# STM32WB55x register map
File version: 1.0
CPU: CM4 r0p1, little endian, 4 interrupt priority bits
Registers are 32-bit, read-write, reset 0x0 unless marked. A register's access mark holds for its fields unless they carry their own. Offsets are from the block's base; [hi:lo] are bit positions; {n}, {i} and the like mark numbered series; 'fields as' and 'values as' point back to an identical list.

## TIM2
Base 0x40000000
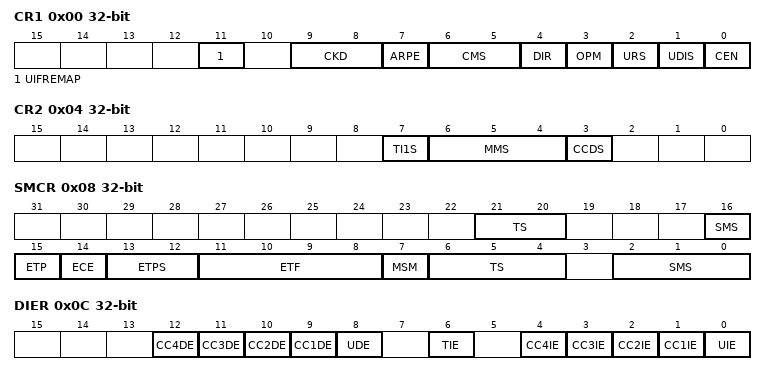
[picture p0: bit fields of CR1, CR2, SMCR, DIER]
0x00 CR1
  [11] UIFREMAP, [9:8] CKD, [7] ARPE, [6:5] CMS, [4] DIR, [3] OPM, [2] URS, [1] UDIS, [0] CEN
0x04 CR2
  [7] TI1S, [6:4] MMS, [3] CCDS
0x08 SMCR
  [21:20] TS, [16] SMS, [15] ETP, [14] ECE, [13:12] ETPS, [11:8] ETF, [7] MSM, [6:4] TS, [2:0] SMS
0x0C DIER
  [n+8] CC{n}DE (n=1..4), [8] UDE, [6] TIE, [n] CC{n}IE (n=1..4), [0] UIE
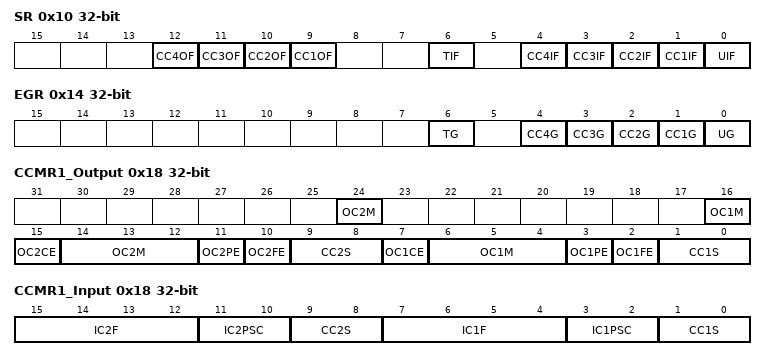
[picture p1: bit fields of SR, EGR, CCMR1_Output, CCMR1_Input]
0x10 SR
  [n+8] CC{n}OF (n=1..4), [6] TIF, [n] CC{n}IF (n=1..4), [0] UIF
0x14 EGR
  [6] TG, [n] CC{n}G (n=1..4), [0] UG
0x18 CCMR1_Output
  [24] OC2M, [16] OC1M, [15] OC2CE, [14:12] OC2M, [11] OC2PE, [10] OC2FE, [9:8] CC2S, [7] OC1CE, [6:4] OC1M, [3] OC1PE, [2] OC1FE, [1:0] CC1S
0x18 CCMR1_Input
  [15:12] IC2F, [11:10] IC2PSC, [9:8] CC2S, [7:4] IC1F, [3:2] IC1PSC, [1:0] CC1S
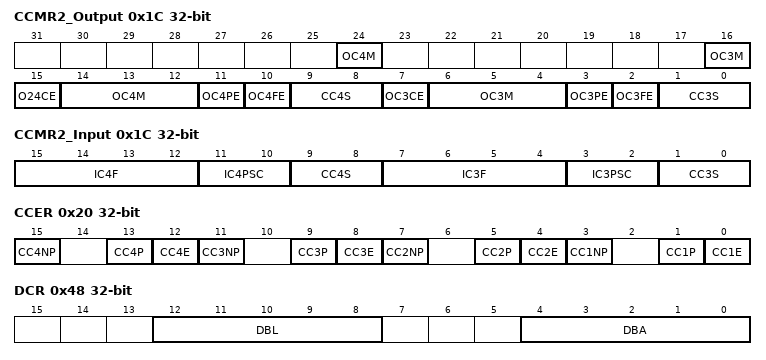
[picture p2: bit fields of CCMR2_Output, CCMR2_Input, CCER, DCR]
0x1C CCMR2_Output
  [24] OC4M, [16] OC3M, [15] O24CE, [14:12] OC4M, [11] OC4PE, [10] OC4FE, [9:8] CC4S, [7] OC3CE, [6:4] OC3M, [3] OC3PE, [2] OC3FE, [1:0] CC3S
0x1C CCMR2_Input
  [15:12] IC4F, [11:10] IC4PSC, [9:8] CC4S, [7:4] IC3F, [3:2] IC3PSC, [1:0] CC3S
0x20 CCER
  [4n-1] CC{n}NP (n=1..4), [4n-3] CC{n}P (n=1..4), [4n-4] CC{n}E (n=1..4)
0x24 CNT
0x28 PSC
  [15:0] PSC
0x2C ARR
{0x30+4i} CCR{i} (i=1..4)
0x48 DCR
  [12:8] DBL, [4:0] DBA
0x4C DMAR
  [15:0] DMAB
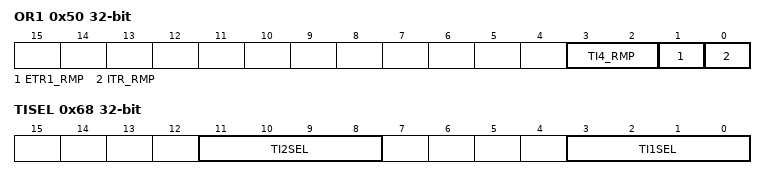
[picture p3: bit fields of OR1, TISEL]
0x50 OR1
  [3:2] TI4_RMP, [1] ETR1_RMP, [0] ITR_RMP
0x60 AF1
  [17:14] ETRSEL
0x68 TISEL
  [11:8] TI2SEL, [3:0] TI1SEL

## TIM16
Base 0x40014400
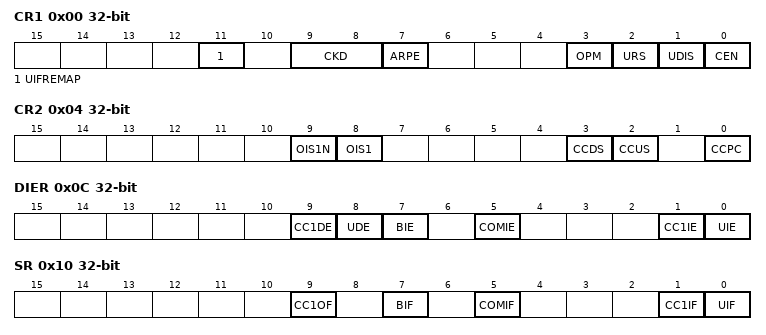
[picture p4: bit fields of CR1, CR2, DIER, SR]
0x00 CR1
  [11] UIFREMAP, [9:8] CKD, [7] ARPE, [3] OPM, [2] URS, [1] UDIS, [0] CEN
0x04 CR2
  [9] OIS1N, [8] OIS1, [3] CCDS, [2] CCUS, [0] CCPC
0x0C DIER
  [9] CC1DE, [8] UDE, [7] BIE, [5] COMIE, [1] CC1IE, [0] UIE
0x10 SR
  [9] CC1OF, [7] BIF, [5] COMIF, [1] CC1IF, [0] UIF
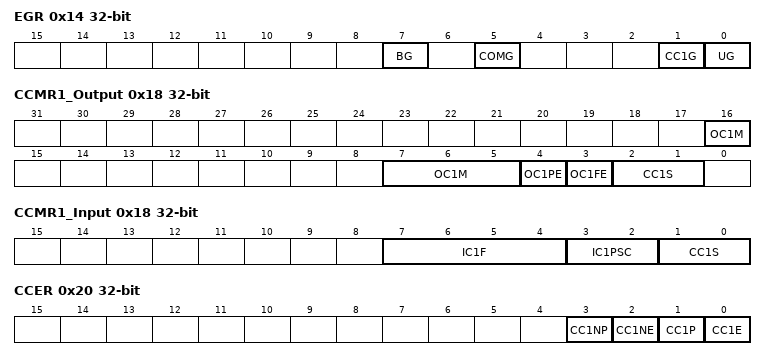
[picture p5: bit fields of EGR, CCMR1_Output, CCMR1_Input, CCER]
0x14 EGR
  [7] BG, [5] COMG, [1] CC1G, [0] UG
0x18 CCMR1_Output
  [16] OC1M, [7:5] OC1M, [4] OC1PE, [3] OC1FE, [2:1] CC1S
0x18 CCMR1_Input
  [7:4] IC1F, [3:2] IC1PSC, [1:0] CC1S
0x20 CCER
  [3] CC1NP, [2] CC1NE, [1] CC1P, [0] CC1E
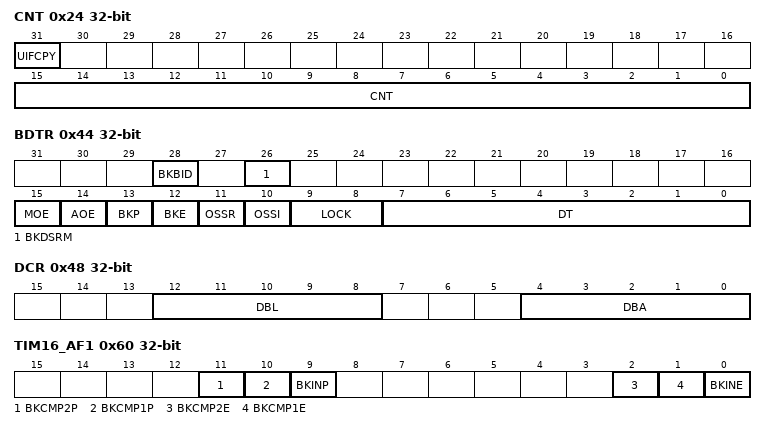
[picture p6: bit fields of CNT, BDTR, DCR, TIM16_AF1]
0x24 CNT
  [31] UIFCPY, [15:0] CNT
0x28 PSC
  [15:0] PSC
0x2C ARR
  [15:0] ARR
0x30 RCR
  [7:0] REP
0x34 CCR1
  [15:0] CCR1
0x44 BDTR
  [28] BKBID, [26] BKDSRM, [15] MOE, [14] AOE, [13] BKP, [12] BKE, [11] OSSR, [10] OSSI, [9:8] LOCK, [7:0] DT
0x48 DCR
  [12:8] DBL, [4:0] DBA
0x4C DMAR
  [15:0] DMAB
0x50 TIM16_OR1
  [1:0] TI1_RMP
0x50 TIM17_OR1
  [1:0] TI1_RMP
0x60 TIM16_AF1
  [11] BKCMP2P, [10] BKCMP1P, [9] BKINP, [2] BKCMP2E, [1] BKCMP1E, [0] BKINE
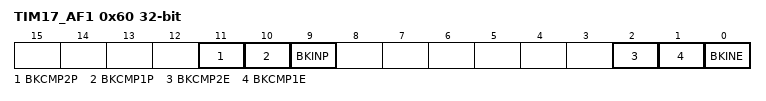
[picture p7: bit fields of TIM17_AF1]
0x60 TIM17_AF1
  fields as TIM16_AF1
0x68 TIM16_TISEL
  [3:0] TI1SEL
0x68 TIM17_TISEL
  [3:0] TI1SEL

## TIM17
Base 0x40014800
Registers as TIM16 (with TIM16 read as TIM17), without TIM17_OR1, TIM17_AF1, TIM17_TISEL; these are added or differ:
0x50 TIM16_OR1
  [1:0] TI1_RMP
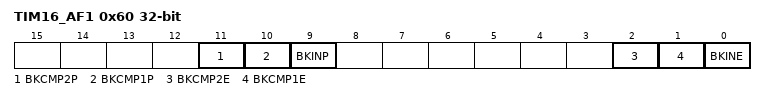
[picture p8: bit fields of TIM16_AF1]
0x60 TIM16_AF1
  [11] BKCMP2P, [10] BKCMP1P, [9] BKINP, [2] BKCMP2E, [1] BKCMP1E, [0] BKINE
0x68 TIM16_TISEL
  [3:0] TI1SEL

## LPTIM1
Base 0x40007C00
Same registers: LPTIM2 0x40008000
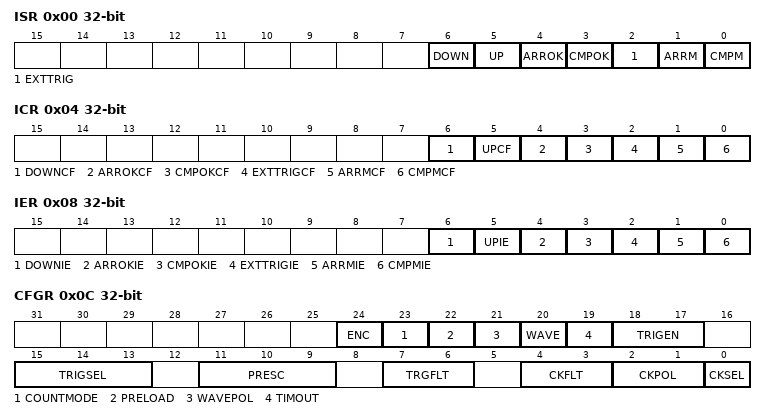
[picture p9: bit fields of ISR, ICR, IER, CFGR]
0x00 ISR
  [6] DOWN, [5] UP, [4] ARROK, [3] CMPOK, [2] EXTTRIG, [1] ARRM, [0] CMPM
0x04 ICR
  [6] DOWNCF, [5] UPCF, [4] ARROKCF, [3] CMPOKCF, [2] EXTTRIGCF, [1] ARRMCF, [0] CMPMCF
0x08 IER
  [6] DOWNIE, [5] UPIE, [4] ARROKIE, [3] CMPOKIE, [2] EXTTRIGIE, [1] ARRMIE, [0] CMPMIE
0x0C CFGR
  [24] ENC, [23] COUNTMODE, [22] PRELOAD, [21] WAVEPOL, [20] WAVE, [19] TIMOUT, [18:17] TRIGEN, [15:13] TRIGSEL, [11:9] PRESC, [7:6] TRGFLT, [4:3] CKFLT, [2:1] CKPOL, [0] CKSEL
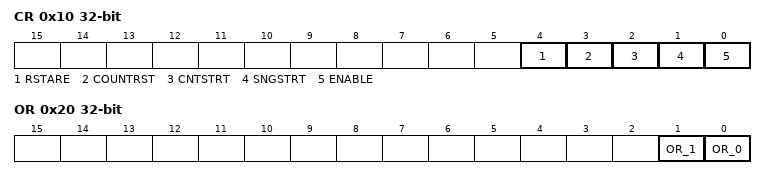
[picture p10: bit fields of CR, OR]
0x10 CR
  [4] RSTARE, [3] COUNTRST, [2] CNTSTRT, [1] SNGSTRT, [0] ENABLE
0x14 CMP
  [15:0] CMP
0x18 ARR
  [15:0] ARR
0x1C CNT
  [15:0] CNT
0x20 OR
  [1] OR_1, [0] OR_0

## MPU — Memory protection unit
Base 0xE000ED90
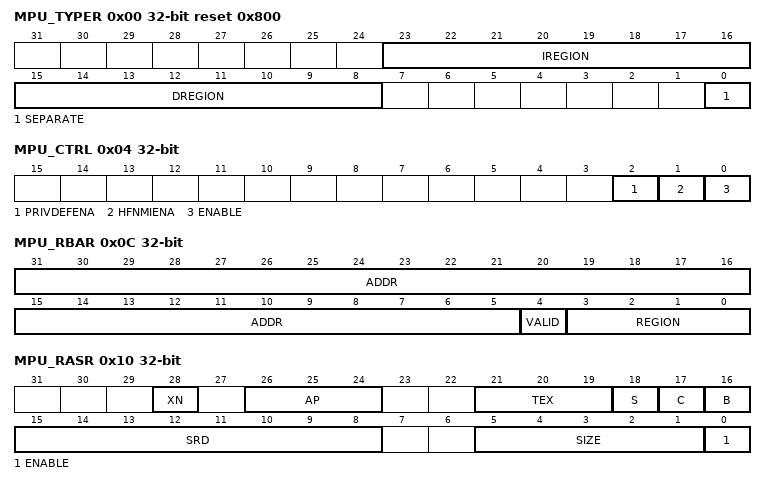
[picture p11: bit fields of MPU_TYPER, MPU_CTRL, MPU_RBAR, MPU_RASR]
0x00 MPU_TYPER ro reset 0x800 — MPU type register
  [23:16] IREGION — Number of MPU instruction regions
  [15:8] DREGION — Number of MPU data regions
  [0] SEPARATE — Separate flag
0x04 MPU_CTRL ro — MPU control register
  [2] PRIVDEFENA — Enable priviliged software access to default memory map
  [1] HFNMIENA — Enables the operation of MPU during hard fault
  [0] ENABLE — Enables the MPU
0x08 MPU_RNR — MPU region number register
  [7:0] REGION — MPU region
0x0C MPU_RBAR — MPU region base address register
  [31:5] ADDR — Region base address field
  [4] VALID — MPU region number valid
  [3:0] REGION — MPU region field
0x10 MPU_RASR — MPU region attribute and size register
  [28] XN — Instruction access disable bit
  [26:24] AP — Access permission
  [21:19] TEX — memory attribute
  [18] S — Shareable memory attribute
  [17] C — memory attribute
  [16] B — memory attribute
  [15:8] SRD — Subregion disable bits
  [5:1] SIZE — Size of the MPU protection region
  [0] ENABLE — Region enable bit.
